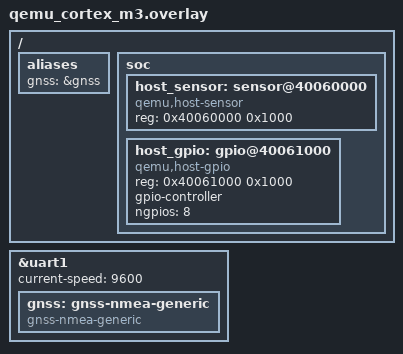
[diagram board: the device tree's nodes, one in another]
/*
 * Copyright (c) 2026
 * SPDX-License-Identifier: Apache-2.0
 *
 * Declares the host-backed peripherals that our patched qemu-wasm Stellaris
 * machine instantiates -- the sensor at 0x40060000 and the GPIO controller at
 * 0x40061000. Both addresses sit in the gap between the last modelled LM3S6965
 * peripheral and the system control block, so they cannot collide with real
 * hardware. See tools/qemu-patches/.
 */

/ {
	aliases {
		gnss = &gnss;
	};

	soc {
		host_sensor: sensor@40060000 {
			compatible = "qemu,host-sensor";
			reg = <0x40060000 0x1000>;
			status = "okay";
		};

		host_gpio: gpio@40061000 {
			compatible = "qemu,host-gpio";
			reg = <0x40061000 0x1000>;
			gpio-controller;
			#gpio-cells = <2>;
			ngpios = <8>;
			status = "okay";
		};
	};
};

&uart1 {
	current-speed = <9600>;
	status = "okay";

	gnss: gnss-nmea-generic {
		compatible = "gnss-nmea-generic";
	};
};
